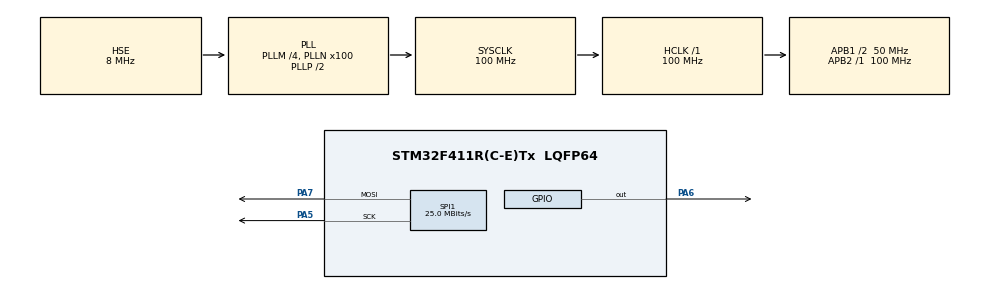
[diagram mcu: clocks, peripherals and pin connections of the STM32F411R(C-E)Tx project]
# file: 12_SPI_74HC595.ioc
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Mcu.Family=STM32F4
Mcu.Name=STM32F411R(C-E)Tx
Mcu.Package=LQFP64
NVIC.PriorityGroup=NVIC_PRIORITYGROUP_4
PA5.Mode=TX_Only_Simplex_Unidirect_Master
PA5.Signal=SPI1_SCK
PA6.Signal=GPIO_Output
PA7.Mode=TX_Only_Simplex_Unidirect_Master
PA7.Signal=SPI1_MOSI
PH0\ -\ OSC_IN.Mode=HSE-External-Oscillator
PH0\ -\ OSC_IN.Signal=RCC_OSC_IN
PH1\ -\ OSC_OUT.Mode=HSE-External-Oscillator
PH1\ -\ OSC_OUT.Signal=RCC_OSC_OUT
ProjectManager.HeapSize=0x200
ProjectManager.StackSize=0x400
ProjectManager.TargetToolchain=STM32CubeIDE
RCC.48MHZClocksFreq_Value=50000000
RCC.AHBFreq_Value=100000000
RCC.APB1CLKDivider=RCC_HCLK_DIV2
RCC.APB1Freq_Value=50000000
RCC.APB1TimFreq_Value=100000000
RCC.APB2Freq_Value=100000000
RCC.APB2TimFreq_Value=100000000
RCC.CortexFreq_Value=100000000
RCC.HCLKFreq_Value=100000000
RCC.HSE_VALUE=8000000
RCC.HSI_VALUE=16000000
RCC.LSE_VALUE=32768
RCC.PLLM=4
RCC.PLLN=100
RCC.PLLSourceVirtual=RCC_PLLSOURCE_HSE
RCC.SYSCLKFreq_VALUE=100000000
RCC.SYSCLKSource=RCC_SYSCLKSOURCE_PLLCLK
RCC.VCOOutputFreq_Value=200000000
SPI1.BaudRatePrescaler=SPI_BAUDRATEPRESCALER_4
SPI1.CalculateBaudRate=25.0 MBits/s
SPI1.Direction=SPI_DIRECTION_2LINES
SPI1.Mode=SPI_MODE_MASTER
SPI1.VirtualType=VM_MASTER
TIM11.Prescaler=100-1
VP_TIM11_VS_ClockSourceINT.Mode=Enable_Timer
board=custom

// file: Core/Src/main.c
/* USER CODE BEGIN Header */
/**
  ******************************************************************************
  * @file           : main.c
  * @brief          : Main program body
  ******************************************************************************
  * @attention
  *
  * Copyright (c) 2025 STMicroelectronics.
  * All rights reserved.
  *
  * This software is licensed under terms that can be found in the LICENSE file
  * in the root directory of this software component.
  * If no LICENSE file comes with this software, it is provided AS-IS.
  *
  ******************************************************************************
  */
/* USER CODE END Header */
#include "main.h"
#include "spi.h"
#include "tim.h"
#include "gpio.h"

/* USER CODE BEGIN PD */

#define __RCLK_HIGH()	HAL_GPIO_WritePin(GPIOA, GPIO_PIN_6, 1)
#define __RCLK_LOW()	HAL_GPIO_WritePin(GPIOA, GPIO_PIN_6, 0)

/* USER CODE END PD */

/* USER CODE BEGIN PV */

uint8_t fnd_1_Data[10] = {
    0x3f, // 0b00111111 => 0 (a b c d e f)
    0x06, // 0b00000110 => 1 (b c)
    0x5b, // 0b01011011 => 2 (a b d e g)
    0x4f, // 0b01001111 => 3 (a b c d g)
    0x66, // 0b01100110 => 4 (b c f g)
    0x6d, // 0b01101101 => 5 (a c d f g)
    0x7d, // 0b01111101 => 6 (a c d e f g)
    0x07, // 0b00000111 => 7 (a b c)
    0x7f, // 0b01111111 => 8 (a b c d e f g)
    0x6f, // 0b01101111 => 9 (a b c d f g)
};

/* USER CODE END PV */

void SystemClock_Config(void);

/* USER CODE BEGIN 0 */

//fnd출력
void fndOut595(uint8_t data)
{

	HAL_SPI_Transmit(&hspi1, &data, 1, HAL_MAX_DELAY);

	__RCLK_HIGH();
	HAL_Delay(500);
	__RCLK_LOW();
	HAL_Delay(500);
}

/* USER CODE END 0 */

int main(void)
{

  /* MCU Configuration--------------------------------------------------------*/

  /* Reset of all peripherals, Initializes the Flash interface and the Systick. */
  HAL_Init();

  /* Configure the system clock */
  SystemClock_Config();

  /* Initialize all configured peripherals */
  MX_GPIO_Init();
  MX_TIM11_Init();
  MX_SPI1_Init();

  /* Infinite loop */
  /* USER CODE BEGIN WHILE */
  while (1)
  {
	  for(uint8_t i=0; i<10; i++)
	  {
		  fndOut595(fnd_1_Data[i]);
		  HAL_Delay(300);
	  }
    /* USER CODE END WHILE */

  }
}

void SystemClock_Config(void)
{
  RCC_OscInitTypeDef RCC_OscInitStruct = {0};
  RCC_ClkInitTypeDef RCC_ClkInitStruct = {0};

  /** Configure the main internal regulator output voltage
  */
  __HAL_RCC_PWR_CLK_ENABLE();
  __HAL_PWR_VOLTAGESCALING_CONFIG(PWR_REGULATOR_VOLTAGE_SCALE1);

  /** Initializes the RCC Oscillators according to the specified parameters
  * in the RCC_OscInitTypeDef structure.
  */
  RCC_OscInitStruct.OscillatorType = RCC_OSCILLATORTYPE_HSE;
  RCC_OscInitStruct.HSEState = RCC_HSE_ON;
  RCC_OscInitStruct.PLL.PLLState = RCC_PLL_ON;
  RCC_OscInitStruct.PLL.PLLSource = RCC_PLLSOURCE_HSE;
  RCC_OscInitStruct.PLL.PLLM = 4;
  RCC_OscInitStruct.PLL.PLLN = 100;
  RCC_OscInitStruct.PLL.PLLP = RCC_PLLP_DIV2;
  RCC_OscInitStruct.PLL.PLLQ = 4;
  if (HAL_RCC_OscConfig(&RCC_OscInitStruct) != HAL_OK)
  {
    Error_Handler();
  }

  /** Initializes the CPU, AHB and APB buses clocks
  */
  RCC_ClkInitStruct.ClockType = RCC_CLOCKTYPE_HCLK|RCC_CLOCKTYPE_SYSCLK
                              |RCC_CLOCKTYPE_PCLK1|RCC_CLOCKTYPE_PCLK2;
  RCC_ClkInitStruct.SYSCLKSource = RCC_SYSCLKSOURCE_PLLCLK;
  RCC_ClkInitStruct.AHBCLKDivider = RCC_SYSCLK_DIV1;
  RCC_ClkInitStruct.APB1CLKDivider = RCC_HCLK_DIV2;
  RCC_ClkInitStruct.APB2CLKDivider = RCC_HCLK_DIV1;

  if (HAL_RCC_ClockConfig(&RCC_ClkInitStruct, FLASH_LATENCY_3) != HAL_OK)
  {
    Error_Handler();
  }
}

void Error_Handler(void)
{
  __disable_irq();
  while (1)
  {
  }
}
